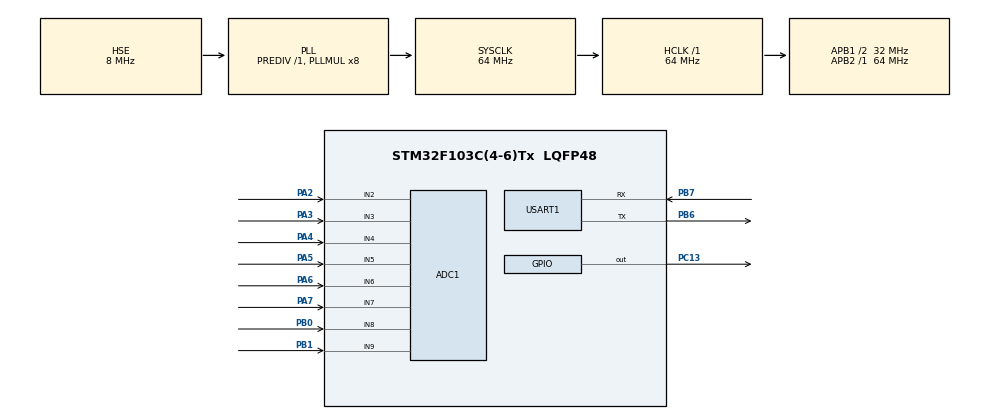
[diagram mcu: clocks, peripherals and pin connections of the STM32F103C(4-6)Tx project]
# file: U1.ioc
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ADC1.Channel-0\#ChannelRegularConversion=ADC_CHANNEL_2
ADC1.NbrOfConversionFlag=1
ADC1.Rank-0\#ChannelRegularConversion=1
ADC1.SamplingTime-0\#ChannelRegularConversion=ADC_SAMPLETIME_1CYCLE_5
ADC1.master=1
Mcu.Family=STM32F1
Mcu.Name=STM32F103C(4-6)Tx
Mcu.Package=LQFP48
NVIC.PriorityGroup=NVIC_PRIORITYGROUP_4
PA13.Mode=Serial_Wire
PA13.Signal=SYS_JTMS-SWDIO
PA14.Mode=Serial_Wire
PA14.Signal=SYS_JTCK-SWCLK
PA2.Signal=ADCx_IN2
PA3.Signal=ADCx_IN3
PA4.Signal=ADCx_IN4
PA5.Signal=ADCx_IN5
PA6.Signal=ADCx_IN6
PA7.Signal=ADCx_IN7
PB0.Signal=ADCx_IN8
PB1.Signal=ADCx_IN9
PB6.Mode=Asynchronous
PB6.Signal=USART1_TX
PB7.Mode=Asynchronous
PB7.Signal=USART1_RX
PC13-TAMPER-RTC.Signal=GPIO_Output
PD0-OSC_IN.Mode=HSE-External-Oscillator
PD0-OSC_IN.Signal=RCC_OSC_IN
PD1-OSC_OUT.Mode=HSE-External-Oscillator
PD1-OSC_OUT.Signal=RCC_OSC_OUT
ProjectManager.HeapSize=0x200
ProjectManager.StackSize=0x400
ProjectManager.TargetToolchain=MDK-ARM V5
RCC.ADCPresc=RCC_ADCPCLK2_DIV6
RCC.AHBFreq_Value=64000000
RCC.APB1CLKDivider=RCC_HCLK_DIV2
RCC.APB1Freq_Value=32000000
RCC.APB1TimFreq_Value=64000000
RCC.APB2Freq_Value=64000000
RCC.APB2TimFreq_Value=64000000
RCC.HCLKFreq_Value=64000000
RCC.PLLMUL=RCC_PLL_MUL16
RCC.SYSCLKFreq_VALUE=64000000
RCC.SYSCLKSource=RCC_SYSCLKSOURCE_PLLCLK
RCC.USBFreq_Value=64000000
SH.ADCx_IN2.0=ADC1_IN2,IN2
SH.ADCx_IN3.0=ADC1_IN3,IN3
SH.ADCx_IN4.0=ADC1_IN4,IN4
SH.ADCx_IN5.0=ADC1_IN5,IN5
SH.ADCx_IN6.0=ADC1_IN6,IN6
SH.ADCx_IN7.0=ADC1_IN7,IN7
SH.ADCx_IN8.0=ADC1_IN8,IN8
SH.ADCx_IN9.0=ADC1_IN9,IN9
USART1.VirtualMode=VM_ASYNC
board=custom

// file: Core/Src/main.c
/* USER CODE BEGIN Header */
/**
  ******************************************************************************
  * @file           : main.c
  * @brief          : M1 测试治具 —— U1（主控1）主程序
  *
  * 功能：
  *   1) PC 协议（USART1 PB6/PB7，115200 8N1，A5 5B 帧）
  *   2) 8 路测试点 ADC 采集（含 VDDA 校准）
  *   3) 对射传感器检测（ADC4/ADC5 + 阈值/回差/去抖）
  *
  * 时钟：HSE 8MHz × 8 = 64MHz（原 CubeMX 生成的是 HSI，已改；见 SystemClock_Config）
  ******************************************************************************
  */
/* USER CODE END Header */
#include "main.h"
#include "adc.h"
#include "usart.h"
#include "gpio.h"

/* USER CODE BEGIN Includes */
#include "app_config.h"
#include "app.h"
#include "bsp_adc.h"
#include "bsp_clock.h"
#include "bsp_uart.h"
#include "protocol.h"
/* USER CODE END Includes */

void SystemClock_Config(void);

int main(void)
{

  /* MCU Configuration--------------------------------------------------------*/

  /* Reset of all peripherals, Initializes the Flash interface and the Systick. */
  HAL_Init();

  /* Configure the system clock */
  SystemClock_Config();

  /* USER CODE BEGIN SysInit */
  BSP_Clock_Init();    /* 兜底：确保 HSE 64MHz（CubeMX 重新生成后仍然有效） */
  /* USER CODE END SysInit */

  /* Initialize all configured peripherals */
  MX_GPIO_Init();
  MX_ADC1_Init();
  MX_USART1_UART_Init();
  /* USER CODE BEGIN 2 */
  BSP_ADC_Init();      /* ADC 自校准 + VDDA 反算 */
  BSP_UART_Init();     /* PC_UART_BAUD + DMA 接收 */
  APP_Init();          /* 对射初始化 + 首轮快照 */
  PROTO_Init();
  /* USER CODE END 2 */

  /* Infinite loop */
  while (1)
  {

    /* USER CODE BEGIN 3 */
    PROTO_Run();       /* 收帧 / 分发 / 回 ACK */
    APP_Poll();        /* 对射采样 + 后台 ADC 快照 + 心跳灯 */
  }
  /* USER CODE END 3 */
}

void SystemClock_Config(void)
{
  RCC_OscInitTypeDef RCC_OscInitStruct = {0};
  RCC_ClkInitTypeDef RCC_ClkInitStruct = {0};
  RCC_PeriphCLKInitTypeDef PeriphClkInit = {0};

  /* 8MHz 外部晶振（原理图 X1/X2）→ 64MHz */
  RCC_OscInitStruct.OscillatorType = RCC_OSCILLATORTYPE_HSE;
  RCC_OscInitStruct.HSEState = RCC_HSE_ON;
  RCC_OscInitStruct.HSEPredivValue = RCC_HSE_PREDIV_DIV1;
  RCC_OscInitStruct.PLL.PLLState = RCC_PLL_ON;
  RCC_OscInitStruct.PLL.PLLSource = RCC_PLLSOURCE_HSE;
  RCC_OscInitStruct.PLL.PLLMUL = RCC_PLL_MUL8;
  if (HAL_RCC_OscConfig(&RCC_OscInitStruct) != HAL_OK)
  {
    /* 晶振未起振（焊接/虚焊）→ 退回内部 HSI，仍保持 64MHz 以便通信 */
    RCC_OscInitStruct.OscillatorType = RCC_OSCILLATORTYPE_HSI;
    RCC_OscInitStruct.HSIState = RCC_HSI_ON;
    RCC_OscInitStruct.HSICalibrationValue = RCC_HSICALIBRATION_DEFAULT;
    RCC_OscInitStruct.PLL.PLLState = RCC_PLL_ON;
    RCC_OscInitStruct.PLL.PLLSource = RCC_PLLSOURCE_HSI_DIV2;
    RCC_OscInitStruct.PLL.PLLMUL = RCC_PLL_MUL16;
    if (HAL_RCC_OscConfig(&RCC_OscInitStruct) != HAL_OK)
    {
      Error_Handler();
    }
  }

  /** Initializes the CPU, AHB and APB buses clocks
  */
  RCC_ClkInitStruct.ClockType = RCC_CLOCKTYPE_HCLK|RCC_CLOCKTYPE_SYSCLK
                              |RCC_CLOCKTYPE_PCLK1|RCC_CLOCKTYPE_PCLK2;
  RCC_ClkInitStruct.SYSCLKSource = RCC_SYSCLKSOURCE_PLLCLK;
  RCC_ClkInitStruct.AHBCLKDivider = RCC_SYSCLK_DIV1;
  RCC_ClkInitStruct.APB1CLKDivider = RCC_HCLK_DIV2;
  RCC_ClkInitStruct.APB2CLKDivider = RCC_HCLK_DIV1;

  if (HAL_RCC_ClockConfig(&RCC_ClkInitStruct, FLASH_LATENCY_2) != HAL_OK)
  {
    Error_Handler();
  }
  PeriphClkInit.PeriphClockSelection = RCC_PERIPHCLK_ADC;
  PeriphClkInit.AdcClockSelection = RCC_ADCPCLK2_DIV6;   /* 10.67MHz ≤ 14MHz */
  if (HAL_RCCEx_PeriphCLKConfig(&PeriphClkInit) != HAL_OK)
  {
    Error_Handler();
  }
}

void Error_Handler(void)
{
  __disable_irq();
  while (1)
  {
  }
}
